# ATSAMA5D36 register map
Vendor: Microchip Technology; Series: SAMA5D3; File version: 0
Registers are 32-bit, read-write, reset 0x0 unless marked. A register's access mark holds for its fields unless they carry their own. Offsets are from the block's base; [hi:lo] are bit positions; {n}, {i} and the like mark numbered series; 'fields as' and 'values as' point back to an identical list.

## SCKC — Slow Clock Controller
Base 0xFFFFFE50
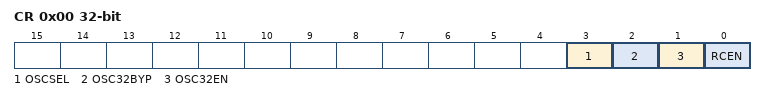
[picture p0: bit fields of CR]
0x00 CR — Slow Clock Controller Configuration Register
  [3] OSCSEL — Slow Clock Selector
    0=RC (Slow clock is the embedded 32 kHz (typical) RC oscillator.); 1=XTAL (Slow clock is the 32.768 kHz crystal oscillator.)
  [2] OSC32BYP — 32.768 kHz Crystal Oscillator Bypass
  [1] OSC32EN — 32.768 kHz Crystal Oscillator
  [0] RCEN — Embedded 32 kHz (typical) RC Oscillator

## SFR — Special Function Registers
Base 0xF0038000
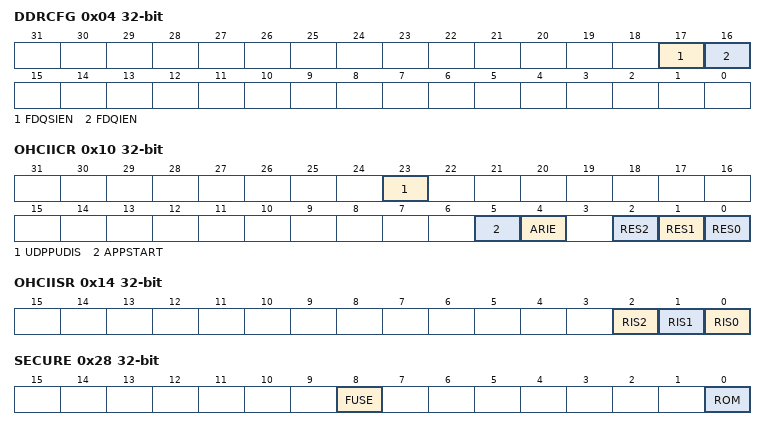
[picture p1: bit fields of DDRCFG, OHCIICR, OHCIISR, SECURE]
0x04 DDRCFG — DDR Configuration Register
  [17] FDQSIEN — Force DDR_DQS Input Buffer Always On
  [16] FDQIEN — Force DDR_DQ Input Buffer Always On
0x10 OHCIICR — OHCI Interrupt Configuration Register
  [23] UDPPUDIS — USB DEVICE PULL-UP DISABLE
  [5] APPSTART
  [4] ARIE — OHCI Asynchronous Resume Interrupt Enable
  [2] RES2 — USB PORTx RESET
  [1] RES1 — USB PORTx RESET
  [0] RES0 — USB PORTx RESET
0x14 OHCIISR ro — OHCI Interrupt Status Register
  [2] RIS2 — OHCI Resume Interrupt Status Port 2
  [1] RIS1 — OHCI Resume Interrupt Status Port 1
  [0] RIS0 — OHCI Resume Interrupt Status Port 0
0x28 SECURE — Security Configuration Register
  [8] FUSE — Disable Access to Fuse Controller
  [0] ROM — Disable Access to ROM Code
0x30 UTMICKTRIM — UTMI Clock Trimming Register
  [1:0] FREQ — UTMI Reference Clock Frequency
    0=12 MHz reference clock; 1=16 MHz reference clock; 2=24 MHz reference clock; 3=48 MHz reference clock
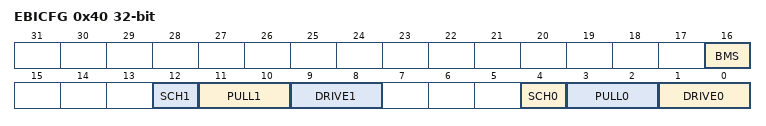
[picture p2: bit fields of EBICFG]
0x40 EBICFG — EBI Configuration Register
  [16] BMS — BMS Sampled Value (Read Only)
    0=ROM (Boot on ROM.); 1=EBI (Boot on EBI.)
  [12] SCH1 — EBI Pins Schmitt Trigger
  [11:10] PULL1 — EBI Pins Pull Value
    0=UP (Pull-up); 1=NONE (No Pull); 3=DOWN (Pull-down)
  [9:8] DRIVE1 — EBI Pins Drive Level
    0=LOW (Low drive level); 2=MEDIUM (Medium drive level); 3=HIGH (High drive level)
  [4] SCH0 — EBI Pins Schmitt Trigger
  [3:2] PULL0 — EBI Pins Pull Value
    0=UP (Pull-up); 1=NONE (No Pull); 3=DOWN (Pull-down)
  [1:0] DRIVE0 — EBI Pins Drive Level
    values as DRIVE1

## SHA — Secure Hash Algorithm
Base 0xF8034000
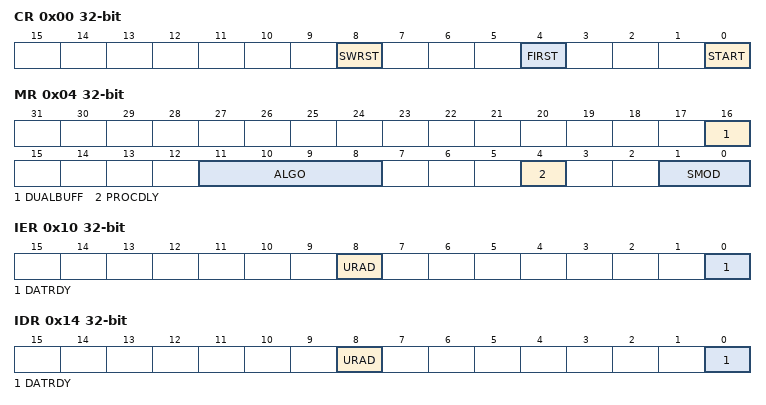
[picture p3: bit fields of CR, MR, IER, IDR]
0x00 CR wo — Control Register
  [8] SWRST — Software Reset
  [4] FIRST — First Block of a Message
  [0] START — Start Processing
0x04 MR — Mode Register
  [16] DUALBUFF — Dual Input Buffer
    0=INACTIVE (SHA_IDATARx and SHA_IODATARx cannot be written during processing of previous block.); 1=ACTIVE (SHA_IDATARx and SHA_IODATARx can be written during processing of previous block when SMOD value = 2. It speeds up the overall runtime of large files.)
  [11:8] ALGO — SHA Algorithm
    0=SHA1 (SHA1 algorithm processed); 1=SHA256 (SHA256 algorithm processed); 2=SHA384 (SHA384 algorithm processed); 3=SHA512 (SHA512 algorithm processed); 4=SHA224 (SHA224 algorithm processed)
  [4] PROCDLY — Processing Delay
    0=SHORTEST (SHA processing runtime is the shortest one); 1=LONGEST (SHA processing runtime is the longest one (reduces the SHA bandwidth requirement, reduces the system bus overload))
  [1:0] SMOD — Start Mode
    0=MANUAL_START (Manual Mode); 1=AUTO_START (Auto Mode); 2=IDATAR0_START (SHA_IDATAR0 access only Auto Mode)
0x10 IER wo — Interrupt Enable Register
  [8] URAD — Unspecified Register Access Detection Interrupt Enable
  [0] DATRDY — Data Ready Interrupt Enable
0x14 IDR wo — Interrupt Disable Register
  [8] URAD — Unspecified Register Access Detection Interrupt Disable
  [0] DATRDY — Data Ready Interrupt Disable
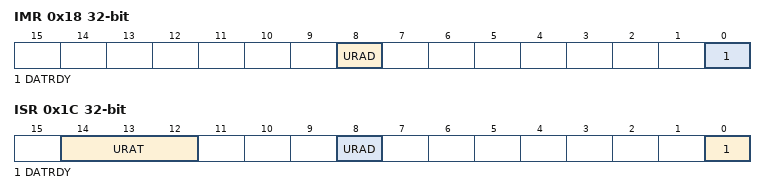
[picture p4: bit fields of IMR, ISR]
0x18 IMR ro — Interrupt Mask Register
  [8] URAD — Unspecified Register Access Detection Interrupt Mask
  [0] DATRDY — Data Ready Interrupt Mask
0x1C ISR ro — Interrupt Status Register
  [14:12] URAT — Unspecified Register Access Type (cleared by writing a 1 to SWRST bit in SHA_CR)
  [8] URAD — Unspecified Register Access Detection Status (cleared by writing a 1 to SWRST bit in SHA_CR)
  [0] DATRDY — Data Ready (cleared by writing a 1 to bit SWRST or START in SHA_CR, or by reading SHA_IODATARx)
{0x40+4i} IDATAR[{i}] (i=0..15) wo — Input Data 0 Register
  [31:0] IDATA — Input Data
{0x80+4i} IODATAR[{i}] (i=0..15) — Input/Output Data 0 Register
  [31:0] IODATA — Input/Output Data
